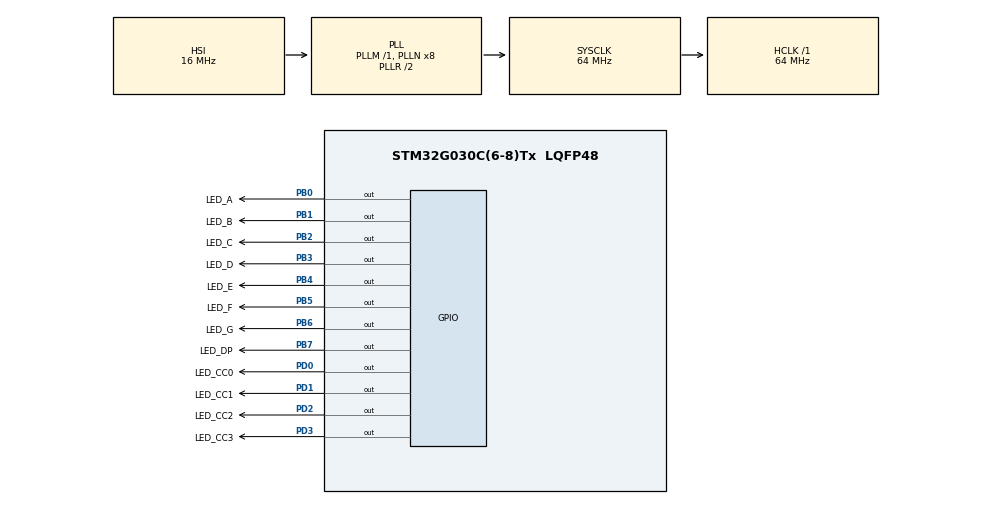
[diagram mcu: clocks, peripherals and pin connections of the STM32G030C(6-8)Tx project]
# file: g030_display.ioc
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Mcu.Family=STM32G0
Mcu.Name=STM32G030C(6-8)Tx
Mcu.Package=LQFP48
PA13.Mode=Serial_Wire
PA13.Signal=SYS_SWDIO
PA14-BOOT0.Mode=Serial_Wire
PA14-BOOT0.Signal=SYS_SWCLK
PB0.GPIO_Label=LED_A
PB0.GPIO_ModeDefaultOutputPP=GPIO_MODE_OUTPUT_PP
PB0.PinState=GPIO_PIN_SET
PB0.Signal=GPIO_Output
PB1.GPIO_Label=LED_B
PB1.GPIO_ModeDefaultOutputPP=GPIO_MODE_OUTPUT_PP
PB1.PinState=GPIO_PIN_SET
PB1.Signal=GPIO_Output
PB2.GPIO_Label=LED_C
PB2.PinState=GPIO_PIN_SET
PB2.Signal=GPIO_Output
PB3.GPIO_Label=LED_D
PB3.PinState=GPIO_PIN_SET
PB3.Signal=GPIO_Output
PB4.GPIO_Label=LED_E
PB4.PinState=GPIO_PIN_SET
PB4.Signal=GPIO_Output
PB5.GPIO_Label=LED_F
PB5.PinState=GPIO_PIN_SET
PB5.Signal=GPIO_Output
PB6.GPIO_Label=LED_G
PB6.PinState=GPIO_PIN_SET
PB6.Signal=GPIO_Output
PB7.GPIO_Label=LED_DP
PB7.PinState=GPIO_PIN_SET
PB7.Signal=GPIO_Output
PD0.GPIO_Label=LED_CC0
PD0.PinState=GPIO_PIN_SET
PD0.Signal=GPIO_Output
PD1.GPIO_Label=LED_CC1
PD1.PinState=GPIO_PIN_SET
PD1.Signal=GPIO_Output
PD2.GPIO_Label=LED_CC2
PD2.PinState=GPIO_PIN_SET
PD2.Signal=GPIO_Output
PD3.GPIO_Label=LED_CC3
PD3.PinState=GPIO_PIN_SET
PD3.Signal=GPIO_Output
ProjectManager.HeapSize=0x200
ProjectManager.StackSize=0x400
ProjectManager.TargetToolchain=MDK-ARM V5.32
RCC.ADCFreq_Value=64000000
RCC.AHBFreq_Value=64000000
RCC.CortexFreq_Value=64000000
RCC.EXTERNAL_CLOCK_VALUE=12288000
RCC.HCLKFreq_Value=64000000
RCC.HSE_VALUE=8000000
RCC.HSI_VALUE=16000000
RCC.LSE_VALUE=32768
RCC.SYSCLKFreq_VALUE=64000000
RCC.SYSCLKSource=RCC_SYSCLKSOURCE_PLLCLK
RCC.VCOOutputFreq_Value=128000000
board=custom

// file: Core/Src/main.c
/* USER CODE BEGIN Header */
/**
  ******************************************************************************
  * @file           : main.c
  * @brief          : Main program body
  ******************************************************************************
  * @attention
  *
  * Copyright (c) 2023 STMicroelectronics.
  * All rights reserved.
  *
  * This software is licensed under terms that can be found in the LICENSE file
  * in the root directory of this software component.
  * If no LICENSE file comes with this software, it is provided AS-IS.
  *
  ******************************************************************************
  */
/* USER CODE END Header */
#include "main.h"
#include "gpio.h"

/* USER CODE BEGIN Includes */
#include "led_seg_display.h"
/* USER CODE END Includes */

void SystemClock_Config(void);

int main(void)
{

  /* MCU Configuration--------------------------------------------------------*/

  /* Reset of all peripherals, Initializes the Flash interface and the Systick. */
  HAL_Init();

  /* Configure the system clock */
  SystemClock_Config();

  /* Initialize all configured peripherals */
  MX_GPIO_Init();

  /* Infinite loop */
  while (1)
  {

    /* USER CODE BEGIN 3 */
	  HAL_Delay(1000);
	  DisplayDigitUINT32((HAL_GetTick()/100)%1000);
  }
  /* USER CODE END 3 */
}

void SystemClock_Config(void)
{
  RCC_OscInitTypeDef RCC_OscInitStruct = {0};
  RCC_ClkInitTypeDef RCC_ClkInitStruct = {0};

  /** Configure the main internal regulator output voltage
  */
  HAL_PWREx_ControlVoltageScaling(PWR_REGULATOR_VOLTAGE_SCALE1);

  /** Initializes the RCC Oscillators according to the specified parameters
  * in the RCC_OscInitTypeDef structure.
  */
  RCC_OscInitStruct.OscillatorType = RCC_OSCILLATORTYPE_HSI;
  RCC_OscInitStruct.HSIState = RCC_HSI_ON;
  RCC_OscInitStruct.HSIDiv = RCC_HSI_DIV1;
  RCC_OscInitStruct.HSICalibrationValue = RCC_HSICALIBRATION_DEFAULT;
  RCC_OscInitStruct.PLL.PLLState = RCC_PLL_ON;
  RCC_OscInitStruct.PLL.PLLSource = RCC_PLLSOURCE_HSI;
  RCC_OscInitStruct.PLL.PLLM = RCC_PLLM_DIV1;
  RCC_OscInitStruct.PLL.PLLN = 8;
  RCC_OscInitStruct.PLL.PLLP = RCC_PLLP_DIV2;
  RCC_OscInitStruct.PLL.PLLR = RCC_PLLR_DIV2;
  if (HAL_RCC_OscConfig(&RCC_OscInitStruct) != HAL_OK)
  {
    Error_Handler();
  }

  /** Initializes the CPU, AHB and APB buses clocks
  */
  RCC_ClkInitStruct.ClockType = RCC_CLOCKTYPE_HCLK|RCC_CLOCKTYPE_SYSCLK
                              |RCC_CLOCKTYPE_PCLK1;
  RCC_ClkInitStruct.SYSCLKSource = RCC_SYSCLKSOURCE_PLLCLK;
  RCC_ClkInitStruct.AHBCLKDivider = RCC_SYSCLK_DIV1;
  RCC_ClkInitStruct.APB1CLKDivider = RCC_HCLK_DIV1;

  if (HAL_RCC_ClockConfig(&RCC_ClkInitStruct, FLASH_LATENCY_2) != HAL_OK)
  {
    Error_Handler();
  }
}

void Error_Handler(void)
{
  __disable_irq();
  while (1)
  {
  }
}
